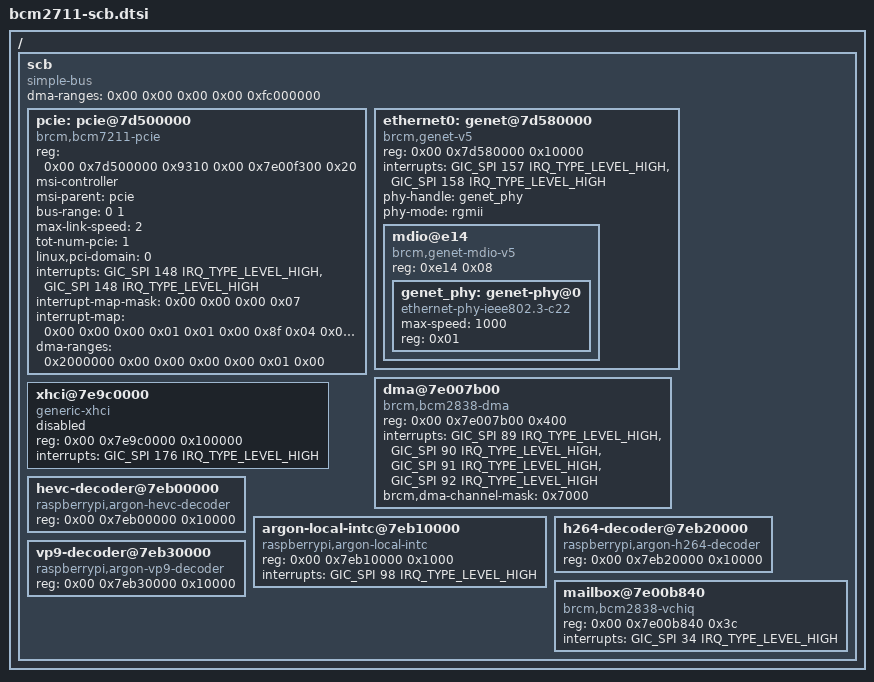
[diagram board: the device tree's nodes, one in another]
#include <dt-bindings/interrupt-controller/arm-gic.h>
#include <dt-bindings/interrupt-controller/irq.h>

/ {

	scb {
		compatible = "simple-bus";
		#address-cells = <2>;
		#size-cells = <1>;
		ranges = < 0x00 0x7c000000 0x00 0xfc000000 0x3800000 0x00 0x40000000 0x00 0xff800000 0x800000 0x06 0x00 0x06 0x00 0x40000000 0x00 0x00 0x00 0x00 0xfc000000 >;
		dma-ranges = < 0x00 0x00 0x00 0x00 0xfc000000 >;
		// phandle = < 0xc0 >;

		pcie: pcie@7d500000 {
			reg = < 0x00 0x7d500000 0x9310 0x00 0x7e00f300 0x20 >;
			msi-controller;
			msi-parent = <&pcie>;
			#address-cells = <3>;
			#interrupt-cells = <1>;
			#size-cells = <2>;
			bus-range = <0 1>;
			compatible = "brcm,bcm7211-pcie", "brcm,bcm7445-pcie", "brcm,pci-plat-dev";
			max-link-speed = <2>;
			tot-num-pcie = <1>;
			linux,pci-domain = <0>;
			interrupts = <GIC_SPI 148 IRQ_TYPE_LEVEL_HIGH>, 
                         <GIC_SPI 148 IRQ_TYPE_LEVEL_HIGH>;
			interrupt-names = "pcie", "msi";
			interrupt-map-mask = < 0x00 0x00 0x00 0x07 >;
			interrupt-map = < 0x00 0x00 0x00 0x01 0x01 0x00 0x8f 0x04 0x00 0x00 0x00 0x02 0x01 0x00 0x90 0x04 0x00 0x00 0x00 0x03 0x01 0x00 0x91 0x04 0x00 0x00 0x00 0x04 0x01 0x00 0x92 0x04 >;
			ranges = < 0x2000000 0x00 0xf8000000 0x06 0x00 0x00 0x4000000 >;
			dma-ranges = < 0x2000000 0x00 0x00 0x00 0x00 0x01 0x00 >;
			status = "okay";
			// phandle = < 0x1e >;
		};

		ethernet0: genet@7d580000 {
			compatible = "brcm,genet-v5";
			reg = < 0x00 0x7d580000 0x10000 >;
			status = "okay";
			#address-cells = <1>;
			#size-cells = <1>;
			interrupts = <GIC_SPI 157 IRQ_TYPE_LEVEL_HIGH>,
                         <GIC_SPI 158 IRQ_TYPE_LEVEL_HIGH>;
			phy-handle = <&genet_phy>;
			phy-mode = "rgmii";
			// phandle = < 0xc1 >;

			mdio@e14 {
				#address-cells = <0>;
				#size-cells = <1>;
				compatible = "brcm,genet-mdio-v5";
				reg = < 0xe14 0x08 >;
				reg-names = "mdio";

				genet_phy: genet-phy@0 {
					compatible = "ethernet-phy-ieee802.3-c22";
					max-speed = <1000>;
					reg = < 0x01 >;
					// phandle = < 0x1f >;
				};
			};
		};

		dma@7e007b00 {
			compatible = "brcm,bcm2838-dma";
			reg = < 0x00 0x7e007b00 0x400 >;
			interrupts = <GIC_SPI 89 IRQ_TYPE_LEVEL_HIGH>,
                         <GIC_SPI 90 IRQ_TYPE_LEVEL_HIGH>,
                         <GIC_SPI 91 IRQ_TYPE_LEVEL_HIGH>,
                         <GIC_SPI 92 IRQ_TYPE_LEVEL_HIGH>;
			interrupt-names = "dma11", "dma12", "dma13", "dma14";
			#dma-cells = <1>;
			brcm,dma-channel-mask = < 0x7000 >;
			// phandle = < 0xc2 >;
		};

		xhci@7e9c0000 {
			compatible = "generic-xhci";
			status = "disabled";
			reg = < 0x00 0x7e9c0000 0x100000 >;
			interrupts = <GIC_SPI 176 IRQ_TYPE_LEVEL_HIGH>;
			// phandle = < 0xc3 >;
		};

		hevc-decoder@7eb00000 {
			compatible = "raspberrypi,argon-hevc-decoder";
			reg = < 0x00 0x7eb00000 0x10000 >;
			status = "okay";
		};

		argon-local-intc@7eb10000 {
			compatible = "raspberrypi,argon-local-intc";
			reg = < 0x00 0x7eb10000 0x1000 >;
			status = "okay";
			interrupts = <GIC_SPI 98 IRQ_TYPE_LEVEL_HIGH>;
		};

		h264-decoder@7eb20000 {
			compatible = "raspberrypi,argon-h264-decoder";
			reg = < 0x00 0x7eb20000 0x10000 >;
			status = "okay";
		};

		vp9-decoder@7eb30000 {
			compatible = "raspberrypi,argon-vp9-decoder";
			reg = < 0x00 0x7eb30000 0x10000 >;
			status = "okay";
		};

		mailbox@7e00b840 {
			compatible = "brcm,bcm2838-vchiq";
			reg = < 0x00 0x7e00b840 0x3c >;
			interrupts = <GIC_SPI 34 IRQ_TYPE_LEVEL_HIGH>;
			// phandle = < 0xc4 >;
		};
	};
};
